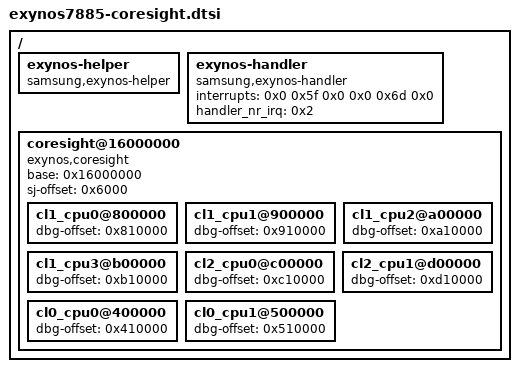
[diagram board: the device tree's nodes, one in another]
/*
 * SAMSUNG EXYNOS7885 SoC device tree source
 *
 * Copyright (c) 2018 Samsung Electronics Co., Ltd.
 *		http://www.samsung.com
 *
 * This program is free software; you can redistribute it and/or modify
 * it under the terms of the GNU General Public License version 2 as
 * published by the Free Software Foundation.
*/

/ {
	exynos-helper {
		compatible = "samsung,exynos-helper";
	};

	exynos-handler {
		compatible = "samsung,exynos-handler";
		interrupts = <0x0 0x5f 0x0 0x0 0x6d 0x0>;
		handler_nr_irq = <0x2>;
	};

	coresight@16000000 {
		compatible = "exynos,coresight";
		base = <0x16000000>;
		sj-offset = <0x6000>;

		cl1_cpu0@800000 {
			device_type = "cs";
			dbg-offset = <0x810000>;
		};

		cl1_cpu1@900000 {
			device_type = "cs";
			dbg-offset = <0x910000>;
		};

		cl1_cpu2@a00000 {
			device_type = "cs";
			dbg-offset = <0xa10000>;
		};

		cl1_cpu3@b00000 {
			device_type = "cs";
			dbg-offset = <0xb10000>;
		};

		cl2_cpu0@c00000 {
			device_type = "cs";
			dbg-offset = <0xc10000>;
		};

		cl2_cpu1@d00000 {
			device_type = "cs";
			dbg-offset = <0xd10000>;
		};

		cl0_cpu0@400000 {
			device_type = "cs";
			dbg-offset = <0x410000>;
		};

		cl0_cpu1@500000 {
			device_type = "cs";
			dbg-offset = <0x510000>;
		};
	};

};
